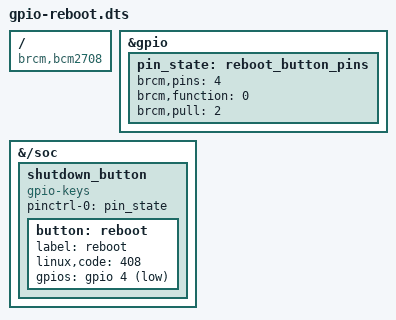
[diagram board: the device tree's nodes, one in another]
// Definitions for gpio-reboot module
/dts-v1/;
/plugin/;

// This overlay sets up an input device that generates KEY_POWER events
// when a given GPIO pin changes. It defaults to using GPIO44, which can
// also be used to wake up (start) the Rpi again after shutdown. Since
// wakeup is active-low, this defaults to active-low with a pullup
// enabled, but all of this can be changed using overlay parameters 

/ {
	compatible = "brcm,bcm2708";

	fragment@0 {
		// Configure the gpio pin controller
		target = <&gpio>;
		__overlay__ {
			// Define a pinctrl state, that sets up the gpio
			// as an input with a pullup enabled. This does
			// not take effect by itself, only when referenced
			// by a "pinctrl client", as is done below. See:
			//   https://www.kernel.org/doc/Documentation/devicetree/bindings/pinctrl/pinctrl-bindings.txt
			//   https://www.kernel.org/doc/Documentation/devicetree/bindings/pinctrl/brcm,bcm2835-gpio.txt
			pin_state: reboot_button_pins {
				brcm,pins = <4>; // gpio number
				brcm,function = <0>; // 0 = input, 1 = output
				brcm,pull = <2>; // 0 = none, 1 = pull down, 2 = pull up
			};
		};
	};
	fragment@1 {
		// Add a new device to the /soc devicetree node
		target-path = "/soc";
		__overlay__ {
			shutdown_button {
				// Let the gpio-keys driver handle this device. See:
				// https://www.kernel.org/doc/Documentation/devicetree/bindings/input/gpio-keys.txt
				compatible = "gpio-keys";

				// Declare a single pinctrl state (referencing the one declared above) and name it
				// default, so it is activated automatically.
				pinctrl-names = "default";
				pinctrl-0 = <&pin_state>;

				// Enable this device
				status = "okay";

				// Define a single key, called "reboot" that monitors the gpio and sends KEY_RESTART
				button: reboot {
					label = "reboot";
					linux,code = <408>; // KEY_RESTART
					gpios = <&gpio 4 1>;
				};
			};
		};
	};

};
